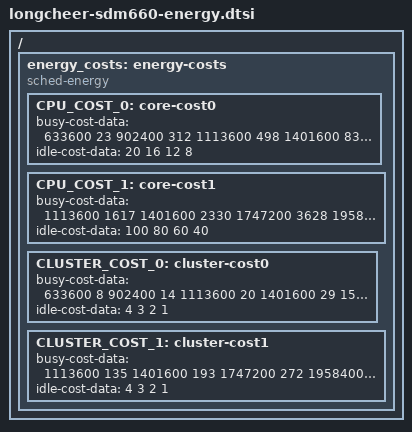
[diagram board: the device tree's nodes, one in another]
/* Copyright (c) 2016-2019, The Linux Foundation. All rights reserved.
 *
 * This program is free software; you can redistribute it and/or modify
 * it under the terms of the GNU General Public License version 2 and
 * only version 2 as published by the Free Software Foundation.
 *
 * This program is distributed in the hope that it will be useful,
 * but WITHOUT ANY WARRANTY; without even the implied warranty of
 * MERCHANTABILITY or FITNESS FOR A PARTICULAR PURPOSE.  See the
 * GNU General Public License for more details.
 */

/ {
	energy_costs: energy-costs {
		compatible = "sched-energy";

		CPU_COST_0: core-cost0 {
			busy-cost-data = <
				 633600   23
				 902400  312
				1113600  498
				1401600  831
				1536000 1033
				1747200 1429
				1843200 1584
			>;
			idle-cost-data = <
				20 16 12 8
			>;
		};
		CPU_COST_1: core-cost1 {
			busy-cost-data = <
				1113600 1617
				1401600 2330
				1747200 3628
				1958400 4820
				2150400 5667
				2208000 6688
			>;
			idle-cost-data = <
				100 80 60 40
			>;
		};
		CLUSTER_COST_0: cluster-cost0 {
			busy-cost-data = <
				 633600 8
				 902400 14
				1113600 20
				1401600 29
				1536000 35
				1747200 49
				1843200 62
			>;
			idle-cost-data = <
				4 3 2 1
			>;
		};
		CLUSTER_COST_1: cluster-cost1 {
			busy-cost-data = <
				1113600 135
				1401600 193
				1747200 272
				1958400 363
				2150400 519
				2208000 585
			>;
			idle-cost-data = <
				4 3 2 1
			>;
		};
	};
};
